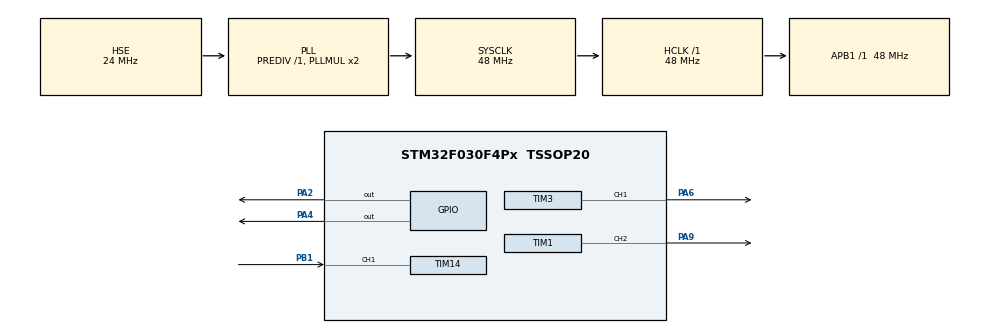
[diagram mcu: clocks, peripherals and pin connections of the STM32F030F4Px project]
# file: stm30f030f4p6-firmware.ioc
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Mcu.Family=STM32F0
Mcu.Name=STM32F030F4Px
Mcu.Package=TSSOP20
NVIC.TIM14_IRQn=true\:0\:0\:false\:false\:true\:true\:true\:true
NVIC.TIM17_IRQn=true\:2\:0\:true\:false\:true\:true\:true\:true
NVIC.TIM3_IRQn=true\:0\:0\:false\:false\:true\:true\:true\:true
PA13.Mode=Serial_Wire
PA13.Signal=SYS_SWDIO
PA14.Mode=Serial_Wire
PA14.Signal=SYS_SWCLK
PA2.PinState=GPIO_PIN_SET
PA2.Signal=GPIO_Output
PA4.Signal=GPIO_Output
PA6.Signal=S_TIM3_CH1
PA9.Signal=S_TIM1_CH2
PB1.Signal=S_TIM14_CH1
PF0-OSC_IN.Mode=HSE-External-Oscillator
PF0-OSC_IN.Signal=RCC_OSC_IN
PF1-OSC_OUT.Mode=HSE-External-Oscillator
PF1-OSC_OUT.Signal=RCC_OSC_OUT
ProjectManager.HeapSize=0x200
ProjectManager.StackSize=0x400
ProjectManager.TargetToolchain=CMake
RCC.AHBFreq_Value=48000000
RCC.APB1Freq_Value=48000000
RCC.APB1TimFreq_Value=48000000
RCC.HCLKFreq_Value=48000000
RCC.HSE_VALUE=24000000
RCC.PLLSourceVirtual=RCC_PLLSOURCE_HSE
RCC.SYSCLKFreq_VALUE=48000000
RCC.SYSCLKSource=RCC_SYSCLKSOURCE_PLLCLK
SH.S_TIM14_CH1.0=TIM14_CH1,Input_Capture1_from_TI1
SH.S_TIM1_CH2.0=TIM1_CH2,PWM Generation2 CH2
SH.S_TIM3_CH1.0=TIM3_CH1,PWM Generation1 CH1
TIM1.Channel-PWM\ Generation2\ CH2=TIM_CHANNEL_2
TIM1.Period=799
TIM1.Prescaler=0
TIM1.TIM_MasterOutputTrigger=TIM_TRGO_OC2REF
TIM14.Channel=TIM_CHANNEL_1
TIM17.Period=99
TIM17.Prescaler=47999
TIM3.Channel-PWM\ Generation1\ CH1=TIM_CHANNEL_1
TIM3.Period=8
TIM3.Pulse-PWM\ Generation1\ CH1=8
VP_TIM14_VS_ClockSourceINT.Mode=Enable_Timer
VP_TIM17_VS_ClockSourceINT.Mode=Enable_Timer
VP_TIM1_VS_ClockSourceINT.Mode=Internal
VP_TIM3_VS_ClockSourceITR.Mode=TriggerSource_ITR0
VP_TIM3_VS_ControllerModeClock.Mode=Clock Mode
VP_TIM3_VS_OPM.Mode=OPM_bit
board=custom

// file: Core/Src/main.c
/* USER CODE BEGIN Header */
/**
  ******************************************************************************
  * @file           : main.c
  * @brief          : Main program body
  ******************************************************************************
  * @attention
  *
  * Copyright (c) 2026 STMicroelectronics.
  * All rights reserved.
  *
  * This software is licensed under terms that can be found in the LICENSE file
  * in the root directory of this software component.
  * If no LICENSE file comes with this software, it is provided AS-IS.
  *
  ******************************************************************************
  */
/* USER CODE END Header */
#include "main.h"
#include "tim.h"
#include "gpio.h"

/* USER CODE BEGIN Includes */
#include "ultrasonic.h"
/* USER CODE END Includes */

void SystemClock_Config(void);

int main(void)
{

  /* MCU Configuration--------------------------------------------------------*/

  /* Reset of all peripherals, Initializes the Flash interface and the Systick. */
  HAL_Init();

  /* Configure the system clock */
  SystemClock_Config();

  /* Initialize all configured peripherals */
  MX_GPIO_Init();
  MX_TIM1_Init();
  MX_TIM3_Init();
  MX_TIM14_Init();
  MX_TIM17_Init();
  /* USER CODE BEGIN 2 */
  SystemClock_UserConfig();
  Ultrasonic_Init();
  Ultrasonic_StartTX();
  /* USER CODE END 2 */

  /* Infinite loop */
  while (1)
  {

    /* USER CODE BEGIN 3 */
    Ultrasonic_ProcessEcho();
    Ultrasonic_BuzzerUpdate();
  }
  /* USER CODE END 3 */
}

void SystemClock_Config(void)
{
  RCC_OscInitTypeDef RCC_OscInitStruct = {0};
  RCC_ClkInitTypeDef RCC_ClkInitStruct = {0};

  /** Initializes the RCC Oscillators according to the specified parameters
  * in the RCC_OscInitTypeDef structure.
  */
  RCC_OscInitStruct.OscillatorType = RCC_OSCILLATORTYPE_HSE;
  RCC_OscInitStruct.HSEState = RCC_HSE_ON;
  RCC_OscInitStruct.PLL.PLLState = RCC_PLL_ON;
  RCC_OscInitStruct.PLL.PLLSource = RCC_PLLSOURCE_HSE;
  RCC_OscInitStruct.PLL.PLLMUL = RCC_PLL_MUL2;
  RCC_OscInitStruct.PLL.PREDIV = RCC_PREDIV_DIV1;
  if (HAL_RCC_OscConfig(&RCC_OscInitStruct) != HAL_OK)
  {
    Error_Handler();
  }

  /** Initializes the CPU, AHB and APB buses clocks
  */
  RCC_ClkInitStruct.ClockType = RCC_CLOCKTYPE_HCLK|RCC_CLOCKTYPE_SYSCLK
                              |RCC_CLOCKTYPE_PCLK1;
  RCC_ClkInitStruct.SYSCLKSource = RCC_SYSCLKSOURCE_PLLCLK;
  RCC_ClkInitStruct.AHBCLKDivider = RCC_SYSCLK_DIV1;
  RCC_ClkInitStruct.APB1CLKDivider = RCC_HCLK_DIV1;

  if (HAL_RCC_ClockConfig(&RCC_ClkInitStruct, FLASH_LATENCY_1) != HAL_OK)
  {
    Error_Handler();
  }
  HAL_RCC_MCOConfig(RCC_MCO, RCC_MCO1SOURCE_SYSCLK, RCC_MCODIV_1);
}

void Error_Handler(void)
{
  __disable_irq();
  while (1)
  {
  }
}
